VERSION ""

NS_ :

BS_:

BU_: Test Cabin CCS

BO_ 291 Standard_Message_1: 8 Vector__XXX

BO_ 2551259973 Event_Msg: 8 Vector__XXX
 SG_ event1 : 0|8@1+ (1,0) [0|255] "" Vector__XXX

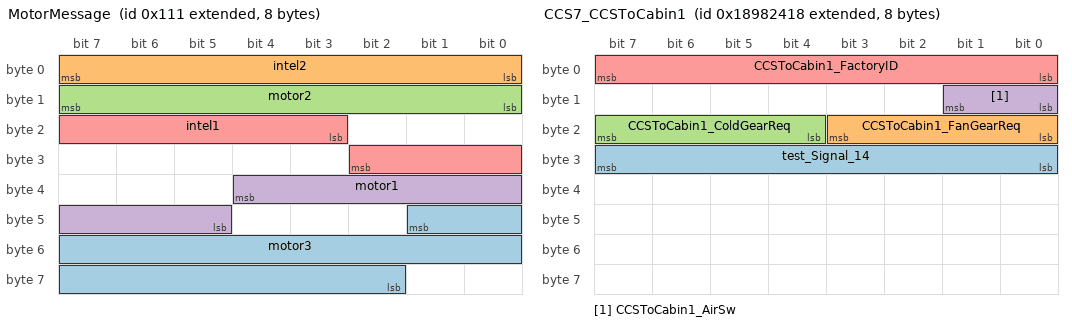
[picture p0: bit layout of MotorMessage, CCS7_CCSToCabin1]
BO_ 2147483921 MotorMessage: 8 Vector__XXX
 SG_ motor3 : 41|16@0+ (1,0) [0|65535] "" Vector__XXX
 SG_ intel2 : 0|8@1+ (1,0) [0|255] "" Vector__XXX
 SG_ motor2 : 15|8@0+ (1,0) [0|255] "" Vector__XXX
 SG_ motor1 : 36|8@0+ (1,0) [0|255] "" Vector__XXX
 SG_ intel1 : 19|8@1+ (1,0) [0|255] "" Vector__XXX

BO_ 2551255586 GroupTest: 8 Test
 SG_ intel2 m1 : 32|8@1+ (1,0) [0|255] "" Vector__XXX
 SG_ intel1 m1 : 24|8@1+ (1,0) [0|255] ""  Cabin,CCS
 SG_ New_Signal_15 m2 : 32|8@1+ (1,0) [0|255] ""  Cabin,CCS
 SG_ test_Signal_14 m2 : 24|8@1+ (0.1,-5.55) [-5|20.5] ""  Cabin,CCS
 SG_ factorID M : 0|4@1+ (10,-20) [-20|130] ""  Cabin,CCS

BO_ 2560104484 Cabin1_CabinToCCS1: 8 Cabin
 SG_ cabin2_sw m2 : 28|2@1+ (1,0) [0|3] ""  CCS,Test
 SG_ CabinToCCS1_RollCnt : 56|8@1+ (1,0) [0|255] ""  CCS,Test
 SG_ CabinToCCS1_FanMotFlt : 24|2@1+ (1,0) [0|3] ""  CCS,Test
 SG_ CabinToCCS1_FanGearSts : 20|4@1+ (1,0) [0|15] ""  CCS,Test
 SG_ CabinToCCS1_FactoryID M : 0|8@1+ (1,0) [0|255] ""  CCS,Test
 SG_ CabinToCCS1_ColdMotFlt : 26|2@1+ (1,0) [0|3] ""  CCS,Test
 SG_ CabinToCCS1_ColdGearSts : 16|4@1+ (1,0) [0|15] ""  CCS,Test
 SG_ CabinToCCS1_CabinTemp : 8|8@1+ (1,-50) [-50|205] ""  CCS,Test
 SG_ CabinToCCS1_AirSts m1 : 28|2@1+ (1,0) [0|3] ""  CCS,Test

BO_ 2560107544 CCS7_CCSToCabin1: 8 Test
 SG_ test_Signal_14 : 24|8@1+ (0.1,-5.55) [-5|20.5] "" Vector__XXX
 SG_ CCSToCabin1_FanGearReq : 16|4@1+ (1,0) [0|15] "" Vector__XXX
 SG_ CCSToCabin1_ColdGearReq : 20|4@1+ (1,0) [0|15] ""  Cabin
 SG_ CCSToCabin1_AirSw : 8|2@1+ (1,0) [0|3] ""  Test,Cabin
 SG_ CCSToCabin1_FactoryID : 0|8@1+ (1,0) [0|255] ""  Cabin

BO_TX_BU_ 2560107544 : Cabin,Test;

CM_ BU_ CCS "中控屏";
CM_ BO_ 2551255586 "测试";
CM_ BO_ 2560104484 "上装发给中控屏1";
CM_ SG_ 2560104484 CabinToCCS1_RollCnt "空调面板计数器.counter自动累加,从0加到255,然后循环，初始值为0，每次报文发送成功(收到ACK)以后，Counter加1；在Busoff出现恢复后，按照off前的值加1继续发送; ECU Reset 以后，Counter值清零。";
CM_ SG_ 2560104484 CabinToCCS1_FanMotFlt "鼓风电机故障状态";
CM_ SG_ 2560104484 CabinToCCS1_FanGearSts "鼓风机档位执行状态";
CM_ SG_ 2560104484 CabinToCCS1_FactoryID "工厂代号，可表示255个工厂,0表示不采用工厂代号";
CM_ SG_ 2560104484 CabinToCCS1_ColdMotFlt "冷热电机故障状态";
CM_ SG_ 2560104484 CabinToCCS1_ColdGearSts "制冷档位实际状态";
CM_ SG_ 2560104484 CabinToCCS1_CabinTemp "货箱实际温度";
CM_ SG_ 2560104484 CabinToCCS1_AirSts "空调实际状态";
CM_ BO_ 2560107544 "中控屏发给上装（发给网关，网关再转给上装）";
CM_ SG_ 2560107544 CCSToCabin1_FanGearReq "鼓风机档位大小请求";
CM_ SG_ 2560107544 CCSToCabin1_ColdGearReq "制冷档位请求";
CM_ SG_ 2560107544 CCSToCabin1_AirSw "空调开关";
CM_ SG_ 2560107544 CCSToCabin1_FactoryID "工厂代号，可表示255个工厂,0表示不采用工厂代号";
BA_DEF_ BO_  "New_AttrDef_9" STRING ;
BA_DEF_ SG_  "GenSigStartValue" INT -255 65535;
BA_DEF_ SG_  "GenSigSendType" ENUM  "Cyclic","OnWrite","OnWriteWithRepetition","OnChange","OnChangeWithRepetition","IfActive","IfActiveWithRepetition","NoSigSendType";
BA_DEF_ BO_  "GenMsgCycleTime" INT 0 65535;
BA_DEF_ BO_  "GenMsgSendType" ENUM  "Cyclic","Event","IfActive","not_used";
BA_DEF_  "DBName" STRING ;
BA_DEF_  "BusType" STRING ;
BA_DEF_DEF_  "New_AttrDef_9" "hello world";
BA_DEF_DEF_  "GenSigStartValue" 0;
BA_DEF_DEF_  "GenSigSendType" "Cyclic";
BA_DEF_DEF_  "GenMsgCycleTime" 200;
BA_DEF_DEF_  "GenMsgSendType" "Cyclic";
BA_DEF_DEF_  "DBName" "shit";
BA_DEF_DEF_  "BusType" "CAN";
BA_ "DBName" "DaPin";
BA_ "GenMsgCycleTime" BO_ 2551259973 500;
BA_ "GenMsgSendType" BO_ 2551259973 1;
BA_ "GenMsgSendType" BO_ 2551255586 3;
BA_ "GenMsgCycleTime" BO_ 2560104484 100;
BA_ "GenMsgSendType" BO_ 2560104484 2;
BA_ "GenMsgSendType" BO_ 2560107544 1;
BA_ "GenMsgCycleTime" BO_ 2560107544 100;
BA_ "GenSigStartValue" SG_ 2551255586 test_Signal_14 155.5;
BA_ "GenSigStartValue" SG_ 2551255586 factorID 4;
BA_ "GenSigStartValue" SG_ 2560104484 CabinToCCS1_CabinTemp 70;
BA_ "GenSigStartValue" SG_ 2560107544 test_Signal_14 155.5;
VAL_ 2560104484 CabinToCCS1_FanMotFlt 0 "无故障，嘟嘟嘟" 1 "短路" 2 "断路" 3 "堵转" ;
VAL_ 2560104484 CabinToCCS1_FanGearSts 15 "无效" 14 "预留" 13 "预留" 12 "预留" 11 "预留" 10 "预留" 9 "预留" 8 "八" 7 "七" 6 "六" 5 "五" 4 "四" 3 "三" 2 "二" 1 "一" 0 "预留" ;
VAL_ 2560104484 CabinToCCS1_ColdMotFlt 3 "堵转" 2 "断路" 1 "短路" 0 "无故障" ;
VAL_ 2560104484 CabinToCCS1_ColdGearSts 15 "无效" 14 "预留" 13 "预留" 12 "预留" 11 "预留" 10 "预留" 9 "预留" 8 "八" 7 "七" 6 "六" 5 "五" 4 "四" 3 "三" 2 "二" 1 "一" 0 "预留" ;
VAL_ 2560104484 CabinToCCS1_AirSts 3 "无效值未使用" 2 "开启" 1 "关闭" 0 "预留" ;
VAL_ 2560107544 CCSToCabin1_FanGearReq 15 "无效" 14 "预留" 13 "预留" 12 "预留" 11 "预留" 10 "预留" 9 "预留" 8 "八" 7 "七" 6 "六" 5 "五" 4 "四" 3 "三" 2 "二" 1 "一" 0 "预留" ;
VAL_ 2560107544 CCSToCabin1_ColdGearReq 15 "无效" 14 "预留" 13 "预留" 12 "预留" 11 "预留" 10 "预留" 9 "预留" 8 "八" 7 "七" 6 "六" 5 "五" 4 "四" 3 "三" 2 "二" 1 "一" 0 "预留" ;
VAL_ 2560107544 CCSToCabin1_AirSw 3 "无效值未使用" 2 "开启" 1 "关闭" 0 "预留" ;
